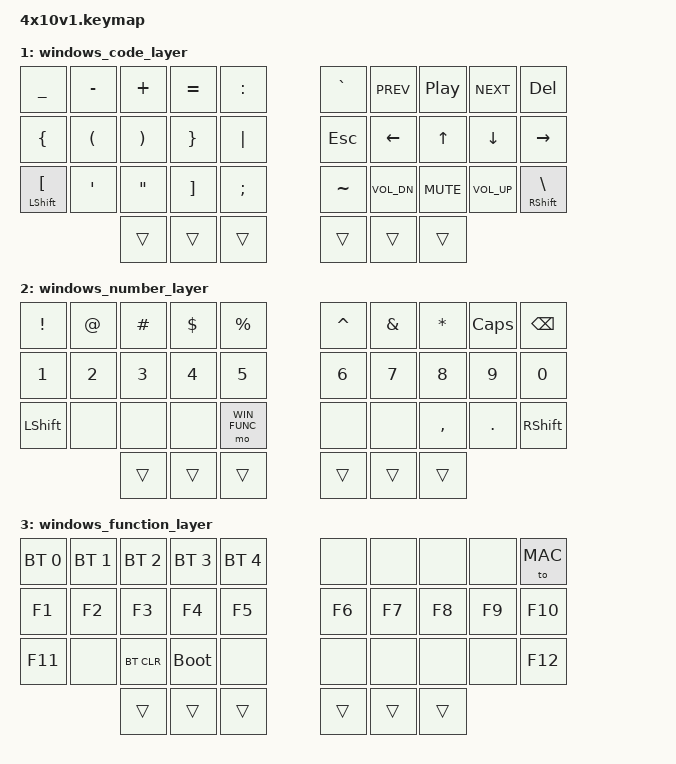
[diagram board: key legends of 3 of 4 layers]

#include <behaviors.dtsi>
#include <dt-bindings/zmk/keys.h>
#include <dt-bindings/zmk/bt.h>
#include <dt-bindings/zmk/outputs.h>



// Layers
#define WIN 0
#define WIN_CODE 1
#define WIN_NUM 2
#define WIN_FUNC 3

// Behavior Overrides
&lt {
    tapping-term-ms = <200>;
    flavor = "hold-preferred";
};

/ {
    //combos {
      //  compatible = "zmk,combos";
        
        //combo_tab {
        //  timeout-ms = <20>;
        //  key-positions = <1 2>;
        //  bindings = <&kp TAB>;
        //};

      //  combo_enter {
        //    timeout-ms = <20>;
          //  key-positions = <13 14>;
            //bindings = <&kp ENTER>;
        //};
    //};

    macros {
        spotlight: spotlight {
            label = "spotlight";
            compatible = "zmk,behavior-macro";
            #binding-cells = <0>;
            bindings = <&macro_press &kp LGUI>, <&macro_tap &kp SPACE>, <&macro_release &kp LGUI>; 
        };

        win_emoji: win_emoji {
            label = "win_emoji";
            compatible = "zmk,behavior-macro";
            #binding-cells = <0>;
            bindings = <&macro_press &kp LGUI>, <&macro_tap &kp DOT>, <&macro_release &kp LGUI>; 
        };
    };

    behaviors {
        td_multi_mac: tap_dance_multi_mac {
            compatible = "zmk,behavior-tap-dance";
            label = "TAP_DANCE_MULTI_MAC";
            #binding-cells = <0>;
            tapping-term-ms = <200>;
            bindings = <&kp ESC>, <&spotlight>, <&mac_emoji>;
        };

        td_multi_windows: tap_dance_multi_windows {
            compatible = "zmk,behavior-tap-dance";
            label = "TAP_DANCE_MULTI_WINDOWS";
            #binding-cells = <0>;
            tapping-term-ms = <200>;
            bindings = <&kp ESC>, <&kp LGUI>, <&win_emoji>;
        };

        bm: bottom_row_mods {
            compatible = "zmk,behavior-hold-tap";
            label = "BOTTOM_ROW_MODS";
            #binding-cells = <2>;
            tapping-term-ms = <135>;
            quick-tap-ms = <0>;
            flavor = "tap-preferred";
            bindings = <&kp>, <&kp>;
        };

        cm: code_row_mods {
            compatible = "zmk,behavior-hold-tap";
            label = "CODE_ROW_MODS";
            #binding-cells = <2>;
            tapping-term-ms = <200>;
            quick-tap-ms = <0>;
            flavor = "tap-preferred";
            bindings = <&kp>, <&kp>;
            retro-tap;
        };

        sm: space_mod {
            compatible = "zmk,behavior-hold-tap";
            label = "SPACE_MOD";
            #binding-cells = <2>;
            flavor = "balanced";
            tapping-term-ms = <200>;
            quick-tap-ms = <125>;
            bindings = <&kp>, <&kp>;
        };
    };

    keymap {
        compatible = "zmk,keymap";

        windows_default_layer {
            bindings = <
                &out OUT_TOG            &kp W          &kp F          &kp P         &kp G                &kp J                 &kp L                  &kp U                  &kp Y        &kp BSPC
                &kp A            &kp R          &kp S          &kp T         &kp D                &kp H                 &kp N                  &kp E                  &kp I        &kp O
                &bm LSHFT Z      &kp X          &kp C          &kp V         &kp B                &kp K                 &kp M                  &kp COMMA              &kp DOT      &bm RSHFT FSLH
                &bootloader      &bt BT_SEL 0   &kp LGUI       &kp LALT      &sm LCTRL SPACE      &lt WIN_CODE TAB      &lt WIN_NUM ENTER      &td_multi_windows
            >;
        };

        windows_code_layer {
            bindings = <
                &kp UNDER           &kp MINUS     &kp PLUS      &kp EQUAL      &kp COLON      &kp GRAVE      &kp C_PREV        &kp C_PP               &kp C_NEXT        &kp DEL
                &kp LBRC            &kp LPAR      &kp RPAR      &kp RBRC       &kp PIPE       &kp ESC        &kp LEFT          &kp UP                 &kp DOWN          &kp RIGHT
                &cm LSHFT LBKT      &kp APOS      &kp DQT       &kp RBKT       &kp SEMI       &kp TILDE      &kp C_VOL_DN      &kp C_MUTE             &kp C_VOL_UP      &cm RSHFT BSLH
                                                  &trans        &trans         &trans         &trans         &trans            &trans
            >;
        };

        windows_number_layer {
            bindings = < 
                &kp EXCL       &kp AT      &kp HASH      &kp DLLR       &kp PRCNT         &kp CARET      &kp AMPS      &kp ASTERISK           &kp CAPS      &kp BSPC  
                &kp N1         &kp N2      &kp N3        &kp N4         &kp N5            &kp N6         &kp N7        &kp N8                 &kp N9        &kp N0
                &kp LSHFT      &none       &none         &none          &mo WIN_FUNC      &none          &none         &kp COMMA              &kp DOT       &kp RSHFT
                                           &trans        &trans         &trans            &trans         &trans        &trans
            >;
        };

        windows_function_layer {
            bindings =<
                &bt BT_SEL 0    &bt BT_SEL 1    &bt BT_SEL 2        &bt BT_SEL 3      &bt BT_SEL 4      &none      &none       &none                  &none       &to MAC
                &kp F1          &kp F2            &kp F3            &kp F4            &kp F5            &kp F6      &kp F7      &kp F8                 &kp F9      &kp F10
                &kp F11         &none             &bt BT_CLR        &bootloader       &none             &none      &none       &none                  &none       &kp F12
                                                  &trans            &trans            &trans            &trans     &trans      &trans      
            >;
        };  
    };
};
